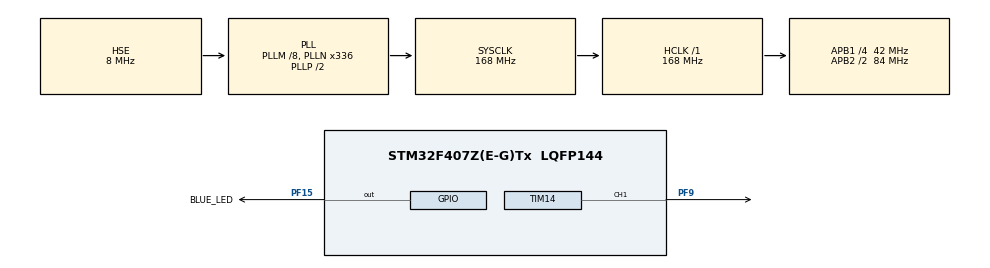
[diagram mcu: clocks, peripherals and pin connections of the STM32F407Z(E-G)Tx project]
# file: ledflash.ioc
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Mcu.Family=STM32F4
Mcu.Name=STM32F407Z(E-G)Tx
Mcu.Package=LQFP144
NVIC.PriorityGroup=NVIC_PRIORITYGROUP_4
PA13.Mode=Serial_Wire
PA13.Signal=SYS_JTMS-SWDIO
PA14.Mode=Serial_Wire
PA14.Signal=SYS_JTCK-SWCLK
PF15.GPIO_Label=BLUE_LED
PF15.Signal=GPIO_Output
PF9.GPIO_Speed=GPIO_SPEED_FREQ_HIGH
PF9.Signal=S_TIM14_CH1
PH0-OSC_IN.Mode=HSE-External-Oscillator
PH0-OSC_IN.Signal=RCC_OSC_IN
PH1-OSC_OUT.Mode=HSE-External-Oscillator
PH1-OSC_OUT.Signal=RCC_OSC_OUT
ProjectManager.HeapSize=0x200
ProjectManager.StackSize=0x400
ProjectManager.TargetToolchain=MDK-ARM V5
RCC.48MHZClocksFreq_Value=84000000
RCC.AHBFreq_Value=168000000
RCC.APB1CLKDivider=RCC_HCLK_DIV4
RCC.APB1Freq_Value=42000000
RCC.APB1TimFreq_Value=84000000
RCC.APB2CLKDivider=RCC_HCLK_DIV2
RCC.APB2Freq_Value=84000000
RCC.APB2TimFreq_Value=168000000
RCC.CortexFreq_Value=168000000
RCC.HCLKFreq_Value=168000000
RCC.HSE_VALUE=8000000
RCC.HSI_VALUE=16000000
RCC.LSE_VALUE=32768
RCC.PLLM=8
RCC.PLLN=336
RCC.PLLSourceVirtual=RCC_PLLSOURCE_HSE
RCC.SYSCLKFreq_VALUE=168000000
RCC.SYSCLKSource=RCC_SYSCLKSOURCE_PLLCLK
RCC.VCOOutputFreq_Value=336000000
SH.S_TIM14_CH1.0=TIM14_CH1,PWM Generation1 CH1
TIM14.Channel=TIM_CHANNEL_1
TIM14.OCPolarity_1=TIM_OCPOLARITY_LOW
TIM14.Period=499
TIM14.Prescaler=83
VP_TIM14_VS_ClockSourceINT.Mode=Enable_Timer
board=custom

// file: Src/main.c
/* USER CODE BEGIN Header */
/**
  ******************************************************************************
  * @file           : main.c
  * @brief          : Main program body
  ******************************************************************************
  * @attention
  *
  * <h2><center>&copy; Copyright (c) 2021 STMicroelectronics.
  * All rights reserved.</center></h2>
  *
  * This software component is licensed by ST under BSD 3-Clause license,
  * the "License"; You may not use this file except in compliance with the
  * License. You may obtain a copy of the License at:
  *                        opensource.org/licenses/BSD-3-Clause
  *
  ******************************************************************************
  */
/* USER CODE END Header */

#include "main.h"

TIM_HandleTypeDef htim14;

/* USER CODE BEGIN PV */
uint16_t indexWave[] = {1,20,40,60,80,100,120,140,160,180,200,220,240,260,280,300,320,340,360,380,
                       400,380,360,340,320,300,280,260,240,220,200,180,160,140,120,100,80,60,40,20};

/* USER CODE END PV */

void SystemClock_Config(void);
static void MX_GPIO_Init(void);
static void MX_TIM14_Init(void);
/* USER CODE BEGIN PFP */
void changepwm(void);

/* USER CODE END PFP */

int main(void)
{

  /* MCU Configuration--------------------------------------------------------*/

  /* Reset of all peripherals, Initializes the Flash interface and the Systick. */
  HAL_Init();

  /* Configure the system clock */
  SystemClock_Config();

  /* Initialize all configured peripherals */
  MX_GPIO_Init();
  MX_TIM14_Init();
  /* USER CODE BEGIN 2 */
  HAL_TIM_PWM_Start(&htim14,TIM_CHANNEL_1);
  /* USER CODE END 2 */

  /* Infinite loop */
  while (1)
  {

    /* USER CODE BEGIN 3 */
		HAL_Delay(100);
		HAL_GPIO_TogglePin(BLUE_LED_GPIO_Port,BLUE_LED_Pin);
		changepwm();

  }
  /* USER CODE END 3 */
}

void SystemClock_Config(void)
{
  RCC_OscInitTypeDef RCC_OscInitStruct = {0};
  RCC_ClkInitTypeDef RCC_ClkInitStruct = {0};

  /** Configure the main internal regulator output voltage
  */
  __HAL_RCC_PWR_CLK_ENABLE();
  __HAL_PWR_VOLTAGESCALING_CONFIG(PWR_REGULATOR_VOLTAGE_SCALE1);
  /** Initializes the CPU, AHB and APB busses clocks
  */
  RCC_OscInitStruct.OscillatorType = RCC_OSCILLATORTYPE_HSE;
  RCC_OscInitStruct.HSEState = RCC_HSE_ON;
  RCC_OscInitStruct.PLL.PLLState = RCC_PLL_ON;
  RCC_OscInitStruct.PLL.PLLSource = RCC_PLLSOURCE_HSE;
  RCC_OscInitStruct.PLL.PLLM = 8;
  RCC_OscInitStruct.PLL.PLLN = 336;
  RCC_OscInitStruct.PLL.PLLP = RCC_PLLP_DIV2;
  RCC_OscInitStruct.PLL.PLLQ = 4;
  if (HAL_RCC_OscConfig(&RCC_OscInitStruct) != HAL_OK)
  {
    Error_Handler();
  }
  /** Initializes the CPU, AHB and APB busses clocks
  */
  RCC_ClkInitStruct.ClockType = RCC_CLOCKTYPE_HCLK|RCC_CLOCKTYPE_SYSCLK
                              |RCC_CLOCKTYPE_PCLK1|RCC_CLOCKTYPE_PCLK2;
  RCC_ClkInitStruct.SYSCLKSource = RCC_SYSCLKSOURCE_PLLCLK;
  RCC_ClkInitStruct.AHBCLKDivider = RCC_SYSCLK_DIV1;
  RCC_ClkInitStruct.APB1CLKDivider = RCC_HCLK_DIV4;
  RCC_ClkInitStruct.APB2CLKDivider = RCC_HCLK_DIV2;

  if (HAL_RCC_ClockConfig(&RCC_ClkInitStruct, FLASH_LATENCY_5) != HAL_OK)
  {
    Error_Handler();
  }
}

static void MX_TIM14_Init(void)
{

  TIM_OC_InitTypeDef sConfigOC = {0};

  htim14.Instance = TIM14;
  htim14.Init.Prescaler = 83;
  htim14.Init.CounterMode = TIM_COUNTERMODE_UP;
  htim14.Init.Period = 499;
  htim14.Init.ClockDivision = TIM_CLOCKDIVISION_DIV1;
  htim14.Init.AutoReloadPreload = TIM_AUTORELOAD_PRELOAD_DISABLE;
  if (HAL_TIM_Base_Init(&htim14) != HAL_OK)
  {
    Error_Handler();
  }
  if (HAL_TIM_PWM_Init(&htim14) != HAL_OK)
  {
    Error_Handler();
  }
  sConfigOC.OCMode = TIM_OCMODE_PWM1;
  sConfigOC.Pulse = 0;
  sConfigOC.OCPolarity = TIM_OCPOLARITY_LOW;
  sConfigOC.OCFastMode = TIM_OCFAST_DISABLE;
  if (HAL_TIM_PWM_ConfigChannel(&htim14, &sConfigOC, TIM_CHANNEL_1) != HAL_OK)
  {
    Error_Handler();
  }
  HAL_TIM_MspPostInit(&htim14);

}

static void MX_GPIO_Init(void)
{
  GPIO_InitTypeDef GPIO_InitStruct = {0};

  /* GPIO Ports Clock Enable */
  __HAL_RCC_GPIOF_CLK_ENABLE();
  __HAL_RCC_GPIOH_CLK_ENABLE();
  __HAL_RCC_GPIOA_CLK_ENABLE();

  /*Configure GPIO pin Output Level */
  HAL_GPIO_WritePin(BLUE_LED_GPIO_Port, BLUE_LED_Pin, GPIO_PIN_RESET);

  /*Configure GPIO pin : BLUE_LED_Pin */
  GPIO_InitStruct.Pin = BLUE_LED_Pin;
  GPIO_InitStruct.Mode = GPIO_MODE_OUTPUT_PP;
  GPIO_InitStruct.Pull = GPIO_NOPULL;
  GPIO_InitStruct.Speed = GPIO_SPEED_FREQ_LOW;
  HAL_GPIO_Init(BLUE_LED_GPIO_Port, &GPIO_InitStruct);

}

/* USER CODE BEGIN 4 */
void changepwm(void)
{
  static uint8_t pwm_index = 1;			/* 用于PWM查表 */

	/* 根据PWM表修改定时器的比较寄存器值 */
	//__HAL_TIM_SetCompare(&htim14,TIM_CHANNEL_1,indexWave[pwm_index]);

	htim14.Instance->CCR1 = indexWave[pwm_index];

	/* 标志PWM表的下一个元素 */
	pwm_index++;
	/* 若PWM脉冲表已经输出完成一遍，重置PWM查表标志 */
	if( pwm_index >=  40)
	{
		pwm_index=0;
	}

}

/* USER CODE END 4 */

void Error_Handler(void)
{
}

/************************ (C) COPYRIGHT STMicroelectronics *****END OF FILE****/
